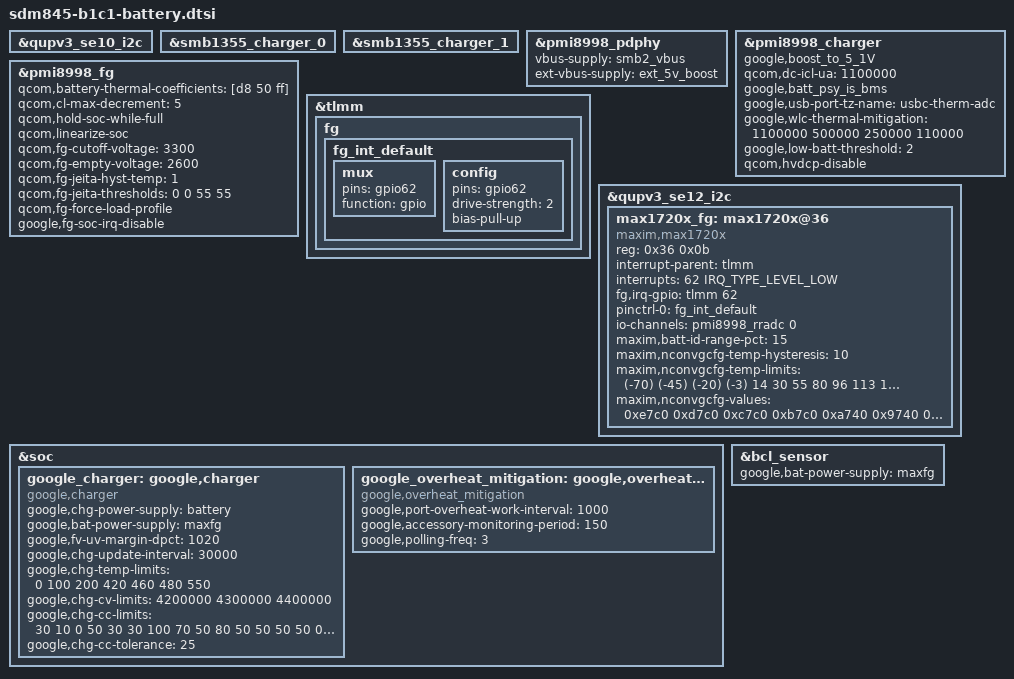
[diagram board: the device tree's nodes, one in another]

&qupv3_se10_i2c {
#include "../qcom/smb1355.dtsi"
};

&smb1355_charger_0 {
	status = "ok";
};

&smb1355_charger_1 {
	status = "ok";
};

&pmi8998_pdphy {
	vbus-supply = <&smb2_vbus>;
	ext-vbus-supply = <&ext_5v_boost>;
};

&pmi8998_charger {
	google,boost_to_5_1V;
	qcom,dc-icl-ua = <1100000>;
	google,batt_psy_is_bms;
	google,usb-port-tz-name = "usbc-therm-adc";
	google,wlc-thermal-mitigation = <1100000 500000 250000 110000>;
	google,low-batt-threshold = <2>;
	qcom,hvdcp-disable;
};

&pmi8998_fg {
	qcom,battery-thermal-coefficients = [d8 50 ff];
	qcom,cl-max-decrement = <5>;
	qcom,hold-soc-while-full;
	qcom,linearize-soc;
	qcom,fg-cutoff-voltage = <3300>;
	qcom,fg-empty-voltage = <2600>;
	qcom,fg-jeita-hyst-temp = <1>;
	qcom,fg-jeita-thresholds = <0 0 55 55>;
	qcom,fg-force-load-profile;
	google,fg-soc-irq-disable;
};

&tlmm {
	fg {
		fg_int_default: fg_int_default {
			mux {
				/* GPIO 62 Maxim FG status change Interrupt */
				pins = "gpio62";
				function = "gpio";
			};

			config {
				pins = "gpio62";
				drive-strength = <2>; /* 2 MA */
				bias-pull-up;
			};
		};

	};
};

/* smart battery: maxim fuel gauge */
&qupv3_se12_i2c {
	status = "ok";
	max1720x_fg: max1720x@36 {
		compatible = "maxim,max1720x";
		reg-names = "m5db", "nvram";
		reg = <0x36 0x0b>;
		interrupt-parent = <&tlmm>;
		interrupt-names = "fg_irq";
		interrupts = <62 IRQ_TYPE_LEVEL_LOW>;
		fg,irq-gpio = <&tlmm 62 0x00>;
		pinctrl-names = "default";
		pinctrl-0 = <&fg_int_default>;

		io-channels = <&pmi8998_rradc 0>;
		io-channel-names = "rradc_batt_id";
		maxim,batt-id-range-pct = <15>;

		maxim,nconvgcfg-temp-hysteresis = <10>;
		maxim,nconvgcfg-temp-limits = /bits/ 16
		    <(-70) (-45) (-20) (-3) 14 30 55 80
		     96 113 130 155 180 230>;
		maxim,nconvgcfg-values = /bits/ 16
		    <0xe7c0 0xd7c0 0xc7c0 0xb7c0 0xa740 0x9740 0x86c0 0x7640
		     0x65c0 0x54c0 0x4440 0x3340 0x2240 0x1140>;
	};
};

&soc {
	google_charger: google,charger {
		compatible = "google,charger";
		google,chg-power-supply = "battery";
		google,bat-power-supply = "maxfg";
		google,fv-uv-margin-dpct = <1020>;
		google,chg-update-interval = <30000>;
		google,chg-temp-limits = <0 100 200 420 460 480 550>;
		google,chg-cv-limits = <4200000 4300000 4400000>;
		google,chg-cc-limits = <
			 30  10   0
			 50  30  30
			100  70  50
			 80  50  50
			 50  50   0
			 30   0   0
		>;
		google,chg-cc-tolerance = <25>;
	};

	google_overheat_mitigation: google,overheat_mitigation {
		compatible = "google,overheat_mitigation";
		google,port-overheat-work-interval = <1000>;
		google,accessory-monitoring-period = <150>;
		/* Must maintain < 1/15 duty cycle */
		google,polling-freq = <3>;
	};
};

&bcl_sensor {
	google,bat-power-supply = "maxfg";
};
